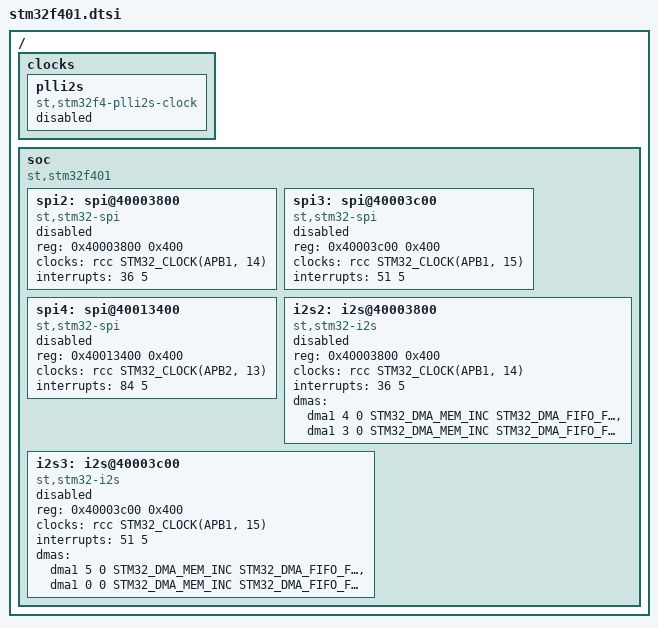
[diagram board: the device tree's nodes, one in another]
/*
 * Copyright (c) 2017 Linaro Limited
 *
 * SPDX-License-Identifier: Apache-2.0
 */

#include <st/f4/stm32f4.dtsi>

/ {
	clocks {
		plli2s: plli2s {
			#clock-cells = <0>;
			compatible = "st,stm32f4-plli2s-clock";
			status = "disabled";
		};
	};

	soc {
		compatible = "st,stm32f401", "st,stm32f4", "simple-bus";

		spi2: spi@40003800 {
			compatible = "st,stm32-spi";
			#address-cells = <1>;
			#size-cells = <0>;
			reg = <0x40003800 0x400>;
			clocks = <&rcc STM32_CLOCK(APB1, 14)>;
			interrupts = <36 5>;
			status = "disabled";
		};

		spi3: spi@40003c00 {
			compatible = "st,stm32-spi";
			#address-cells = <1>;
			#size-cells = <0>;
			reg = <0x40003c00 0x400>;
			clocks = <&rcc STM32_CLOCK(APB1, 15)>;
			interrupts = <51 5>;
			status = "disabled";
		};

		spi4: spi@40013400 {
			compatible = "st,stm32-spi";
			#address-cells = <1>;
			#size-cells = <0>;
			reg = <0x40013400 0x400>;
			clocks = <&rcc STM32_CLOCK(APB2, 13)>;
			interrupts = <84 5>;
			status = "disabled";
		};

		i2s2: i2s@40003800 {
			compatible = "st,stm32-i2s";
			#address-cells = <1>;
			#size-cells = <0>;
			reg = <0x40003800 0x400>;
			clocks = <&rcc STM32_CLOCK(APB1, 14)>;
			interrupts = <36 5>;
			dmas = <&dma1 4 0 STM32_DMA_MEM_INC STM32_DMA_FIFO_FULL
				&dma1 3 0 STM32_DMA_MEM_INC STM32_DMA_FIFO_FULL>;
			dma-names = "tx", "rx";
			status = "disabled";
		};

		i2s3: i2s@40003c00 {
			compatible = "st,stm32-i2s";
			#address-cells = <1>;
			#size-cells = <0>;
			reg = <0x40003c00 0x400>;
			clocks = <&rcc STM32_CLOCK(APB1, 15)>;
			interrupts = <51 5>;
			dmas = <&dma1 5 0 STM32_DMA_MEM_INC STM32_DMA_FIFO_FULL
				&dma1 0 0 STM32_DMA_MEM_INC STM32_DMA_FIFO_FULL>;
			dma-names = "tx", "rx";
			status = "disabled";
		};
	};
};
